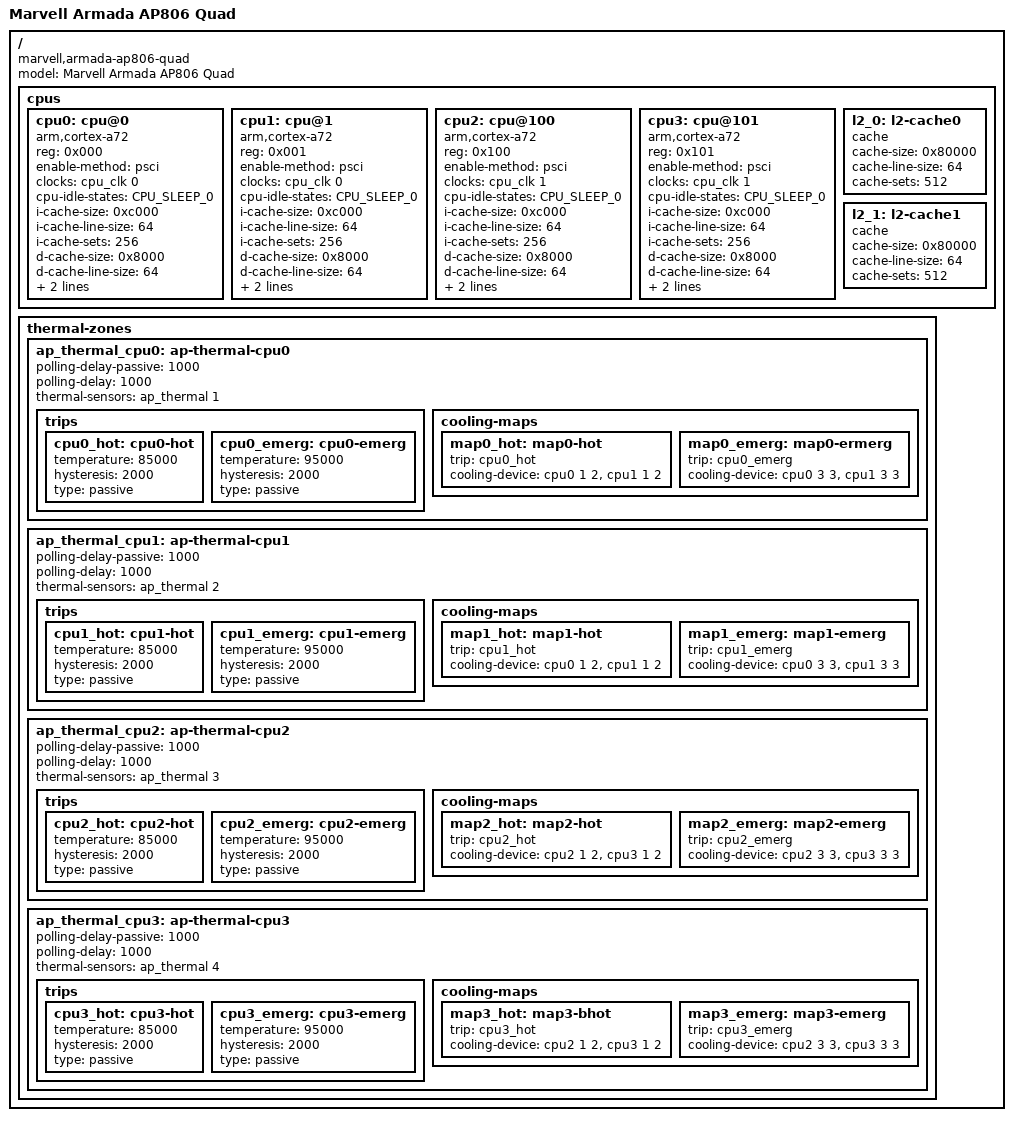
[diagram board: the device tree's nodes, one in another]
// SPDX-License-Identifier: (GPL-2.0+ OR MIT)
/*
 * Copyright (C) 2016 Marvell Technology Group Ltd.
 *
 * Device Tree file for Marvell Armada AP806.
 */

#include "armada-ap806.dtsi"

/ {
	model = "Marvell Armada AP806 Quad";
	compatible = "marvell,armada-ap806-quad", "marvell,armada-ap806";

	cpus {
		#address-cells = <1>;
		#size-cells = <0>;

		cpu0: cpu@0 {
			device_type = "cpu";
			compatible = "arm,cortex-a72", "arm,armv8";
			reg = <0x000>;
			enable-method = "psci";
			#cooling-cells = <2>;
			clocks = <&cpu_clk 0>;
			cpu-idle-states = <&CPU_SLEEP_0>;
			i-cache-size = <0xc000>;
			i-cache-line-size = <64>;
			i-cache-sets = <256>;
			d-cache-size = <0x8000>;
			d-cache-line-size = <64>;
			d-cache-sets = <256>;
			next-level-cache = <&l2_0>;
		};
		cpu1: cpu@1 {
			device_type = "cpu";
			compatible = "arm,cortex-a72", "arm,armv8";
			reg = <0x001>;
			enable-method = "psci";
			#cooling-cells = <2>;
			clocks = <&cpu_clk 0>;
			cpu-idle-states = <&CPU_SLEEP_0>;
			i-cache-size = <0xc000>;
			i-cache-line-size = <64>;
			i-cache-sets = <256>;
			d-cache-size = <0x8000>;
			d-cache-line-size = <64>;
			d-cache-sets = <256>;
			next-level-cache = <&l2_0>;
		};
		cpu2: cpu@100 {
			device_type = "cpu";
			compatible = "arm,cortex-a72", "arm,armv8";
			reg = <0x100>;
			enable-method = "psci";
			#cooling-cells = <2>;
			clocks = <&cpu_clk 1>;
			cpu-idle-states = <&CPU_SLEEP_0>;
			i-cache-size = <0xc000>;
			i-cache-line-size = <64>;
			i-cache-sets = <256>;
			d-cache-size = <0x8000>;
			d-cache-line-size = <64>;
			d-cache-sets = <256>;
			next-level-cache = <&l2_1>;
		};
		cpu3: cpu@101 {
			device_type = "cpu";
			compatible = "arm,cortex-a72", "arm,armv8";
			reg = <0x101>;
			enable-method = "psci";
			#cooling-cells = <2>;
			clocks = <&cpu_clk 1>;
			cpu-idle-states = <&CPU_SLEEP_0>;
			i-cache-size = <0xc000>;
			i-cache-line-size = <64>;
			i-cache-sets = <256>;
			d-cache-size = <0x8000>;
			d-cache-line-size = <64>;
			d-cache-sets = <256>;
			next-level-cache = <&l2_1>;
		};

		l2_0: l2-cache0 {
			compatible = "cache";
			cache-size = <0x80000>;
			cache-line-size = <64>;
			cache-sets = <512>;
		};

		l2_1: l2-cache1 {
			compatible = "cache";
			cache-size = <0x80000>;
			cache-line-size = <64>;
			cache-sets = <512>;
		};
	};

	thermal-zones {
		ap_thermal_cpu0: ap-thermal-cpu0 {
			polling-delay-passive = <1000>;
			polling-delay = <1000>;

			thermal-sensors = <&ap_thermal 1>;

			trips {
				cpu0_hot: cpu0-hot {
					temperature = <85000>;
					hysteresis = <2000>;
					type = "passive";
				};
				cpu0_emerg: cpu0-emerg {
					temperature = <95000>;
					hysteresis = <2000>;
					type = "passive";
				};
			};

			cooling-maps {
				map0_hot: map0-hot {
					trip = <&cpu0_hot>;
					cooling-device = <&cpu0 1 2>,
						<&cpu1 1 2>;
				};
				map0_emerg: map0-ermerg {
					trip = <&cpu0_emerg>;
					cooling-device = <&cpu0 3 3>,
						<&cpu1 3 3>;
				};
			};
		};

		ap_thermal_cpu1: ap-thermal-cpu1 {
			polling-delay-passive = <1000>;
			polling-delay = <1000>;

			thermal-sensors = <&ap_thermal 2>;

			trips {
				cpu1_hot: cpu1-hot {
					temperature = <85000>;
					hysteresis = <2000>;
					type = "passive";
				};
				cpu1_emerg: cpu1-emerg {
					temperature = <95000>;
					hysteresis = <2000>;
					type = "passive";
				};
			};

			cooling-maps {
				map1_hot: map1-hot {
					trip = <&cpu1_hot>;
					cooling-device = <&cpu0 1 2>,
						<&cpu1 1 2>;
				};
				map1_emerg: map1-emerg {
					trip = <&cpu1_emerg>;
					cooling-device = <&cpu0 3 3>,
						<&cpu1 3 3>;
				};
			};
		};

		ap_thermal_cpu2: ap-thermal-cpu2 {
			polling-delay-passive = <1000>;
			polling-delay = <1000>;

			thermal-sensors = <&ap_thermal 3>;

			trips {
				cpu2_hot: cpu2-hot {
					temperature = <85000>;
					hysteresis = <2000>;
					type = "passive";
				};
				cpu2_emerg: cpu2-emerg {
					temperature = <95000>;
					hysteresis = <2000>;
					type = "passive";
				};
			};

			cooling-maps {
				map2_hot: map2-hot {
					trip = <&cpu2_hot>;
					cooling-device = <&cpu2 1 2>,
						<&cpu3 1 2>;
				};
				map2_emerg: map2-emerg {
					trip = <&cpu2_emerg>;
					cooling-device = <&cpu2 3 3>,
						<&cpu3 3 3>;
				};
			};
		};

		ap_thermal_cpu3: ap-thermal-cpu3 {
			polling-delay-passive = <1000>;
			polling-delay = <1000>;

			thermal-sensors = <&ap_thermal 4>;

			trips {
				cpu3_hot: cpu3-hot {
					temperature = <85000>;
					hysteresis = <2000>;
					type = "passive";
				};
				cpu3_emerg: cpu3-emerg {
					temperature = <95000>;
					hysteresis = <2000>;
					type = "passive";
				};
			};

			cooling-maps {
				map3_hot: map3-bhot {
					trip = <&cpu3_hot>;
					cooling-device = <&cpu2 1 2>,
						<&cpu3 1 2>;
				};
				map3_emerg: map3-emerg {
					trip = <&cpu3_emerg>;
					cooling-device = <&cpu2 3 3>,
						<&cpu3 3 3>;
				};
			};
		};
	};
};
